# Z32F0641 register map
Vendor: Zilog, Inc; File version: 1.0
CPU: CM3 r1p0, little endian, no MPU, no FPU, 3 interrupt priority bits
Registers are 32-bit, read-write, reset 0x0 unless marked. A register's access mark holds for its fields unless they carry their own. Offsets are from the block's base; [hi:lo] are bit positions; {n}, {i} and the like mark numbered series.

## T0 — 16-BIT TIMER
Base 0x40003000
Same registers: T1 0x40003020, T2 0x40003040, T3 0x40003060, T8 0x40003100, T9 0x40003120
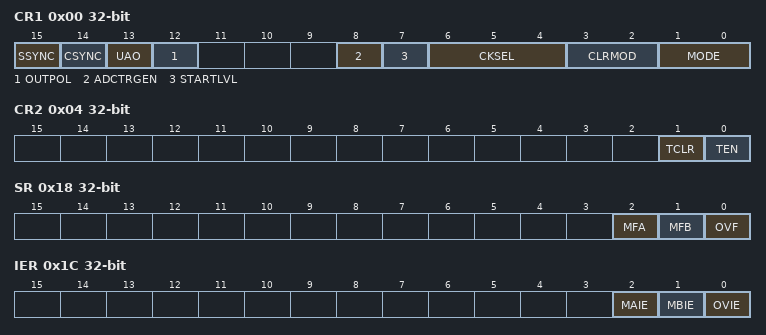
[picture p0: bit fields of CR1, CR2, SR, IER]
0x00 CR1 — Timer n Control Register 1
  [15] SSYNC — Syncronize Start Counter
  [14] CSYNC — Syncronize Clear Counter
  [13] UAO — GRA/GRB Update Mode
  [12] OUTPOL — Timer Output Polarity
  [8] ADCTRGEN
  [7] STARTLVL
  [6:4] CKSEL — counter clock source select
  [3:2] CLRMOD — clear select when capture mode
  [1:0] MODE — Timer operatin mode control
0x04 CR2 — Timer n Control Register 2
  [1] TCLR — Timer register clear
  [0] TEN — Timer enable bit
0x08 PRS — Timer n Prescaler Register
  [9:0] PRS — Prescaler value of count clock
0x0C GRA — Timer n General Register A
  [15:0] GRA
0x10 GRB — Timer n General Register B
  [15:0] GRB
0x14 CNT — Timer n Count Register
  [15:0] CNT
0x18 SR — Timer n Status Register
  [2] MFA — Match register A Flag
  [1] MFB — MATCH register B flag
  [0] OVF — counter overflow falg
0x1C IER — Timer n Interrupt Enable Register
  [2] MAIE — GRA Match interrupt enablee
  [1] MBIE — GRB Match interrupt enable
  [0] OVIE — Counter overflow interrupt enable

## U0 — UNIVERSAL ASYNCHRONOUS RECEIVER/TRANSMITTER
Base 0x40008000
Same registers: U1 0x40008100
0x00 RBR ro — Receive Buffer Register
  [7:0] RBR — recevied/transmit data
0x00 THR wo — Transmit Data Hold Register
  [7:0] THR — recevied/transmit data
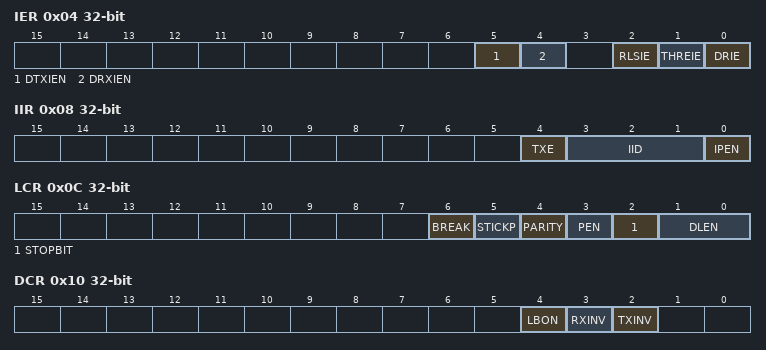
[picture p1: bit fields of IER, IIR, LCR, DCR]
0x04 IER — UART Interrupt Enable Register
  [5] DTXIEN — DMA transmit done interrupt enable
  [4] DRXIEN — DMA Receiver line status interrupt enable
  [2] RLSIE — receiver line status interrupt enable
  [1] THREIE — Transmit holding register empty interrupt enable
  [0] DRIE — Data receive interrupt enable
0x08 IIR — UART Interrupt ID Register
  [4] TXE — TX Interrupt
  [3:1] IID — Interrupt source ID
  [0] IPEN — Interrupt pending bit
0x0C LCR — UART Line Control Register
  [6] BREAK
  [5] STICKP — STICK
  [4] PARITY
  [3] PEN — parity bit transfer enable
  [2] STOPBIT
  [1:0] DLEN — Data length in one transfer word
0x10 DCR — UART Data Control Register
  [4] LBON — Local loopback test mode enable
  [3] RXINV — Rx Data Inversion selection
  [2] TXINV — TX Data Inversion selection
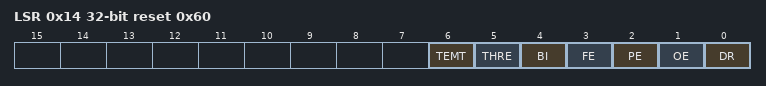
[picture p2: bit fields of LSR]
0x14 LSR reset 0x60 — UART Line Status Register
  [6] TEMT — Transmit empty
  [5] THRE — Transmit holding register empty
  [4] BI — break condition indication bit
  [3] FE — frame error
  [2] PE — parity error
  [1] OE — overrun error
  [0] DR — Data recevied
0x20 BDR — Baud rate Divisor Latch Register
  [15:0] BDR — baudrate setting
0x24 BFR — Baud rate Fraction Counter Register
  [7:0] BFR — Fraction counter value
0x30 IDTR — Inter-frame Delay Time Register
  [2:0] WAITVAL — wait time is decied by this value

## SP0 — SERIAL PERIPHERAL INTERFACE
Base 0x40009000
0x00 RDR ro — SPI n Receive Data Register
  [16:0] RDR — Data
0x00 TDR wo — SPI n Transmit Data Register
  [16:0] TDR — Data
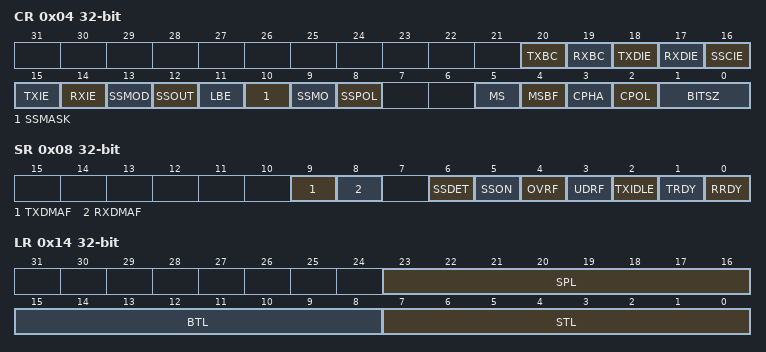
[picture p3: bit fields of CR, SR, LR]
0x04 CR — SPI n Control Register
  [20] TXBC — TX Buffer Clear bit
  [19] RXBC — Recieve buffer Clear bit
  [18] TXDIE — DMA TX Done Interrupt enable bit
  [17] RXDIE — DMA Rx Deone Interrupt enable bit
  [16] SSCIE — SSn Edge Chagne Interrupt enable bit
  [15] TXIE — Transmit interrupt enable bit
  [14] RXIE — Receive interrupt enable bit
  [13] SSMOD — SS Auto/Manual Output select bit
  [12] SSOUT — SS output signal select bit
  [11] LBE — Loop-back mode select bit in master mode
  [10] SSMASK — SS Signal masking bit in slave mode
  [9] SSMO — SS output signal select bit
  [8] SSPOL — SS Signal polarity select bit
  [5] MS — master/slaver select bit
  [4] MSBF — MSB/LSB transmit select bit
  [3] CPHA — SPI clock phase bit
  [2] CPOL — SPI clock polarity bit
  [1:0] BITSZ — Transmit/receive Data bits select bit
0x08 SR — SPI n Status Register
  [9] TXDMAF — DMA transmit Operation complete flag
  [8] RXDMAF — DMA receive Operation complete flag
  [6] SSDET — The rising edge of SS detect flag
  [5] SSON — SS signal status flag
  [4] OVRF — receive overrun error flag
  [3] UDRF — transmit underrun error flag
  [2] TXIDLE ro — transmit/receive operation flag
  [1] TRDY ro — Transmit buffer empty flag
  [0] RRDY ro — receive buffer ready flag
0x0C BR — SPI n Baud Rate Register
  [15:0] BR — buadrate
0x10 EN — SPI n Enable register
  [0] ENABLE — SPI ENABLE bit
0x14 LR — SPI n delay Length Register
  [23:16] SPL — Stop delay length
  [15:8] BTL — Burst delay length
  [7:0] STL — Start delay length

## IC0 — I2C Interface
Base 0x4000A000
0x00 DR — I2C Data Register
  [7:0] DR — Data
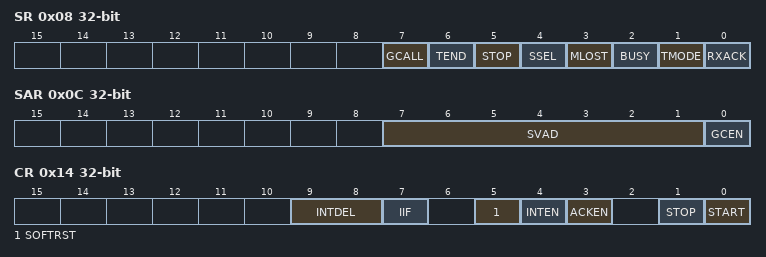
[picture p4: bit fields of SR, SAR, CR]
0x08 SR — Status register
  [7] GCALL — General call flag
  [6] TEND — 1 byte transmission complete flag
  [5] STOP — Stop Flag
  [4] SSEL — slave flag
  [3] MLOST — Mastership lost flag
  [2] BUSY — busy flag
  [1] TMODE — Transmit/reciever mode flag
  [0] RXACK — RX ack flag
0x0C SAR — I2C Slave Address Register
  [7:1] SVAD — 7 bits slave address
  [0] GCEN — general call enable bit
0x14 CR (reset mask 0xFF) — I2C Control Register
  [9:8] INTDEL — Interval Delay between Address and Data
  [7] IIF — Interrupt flag bit
  [5] SOFTRST — Soft reset enable bit
  [4] INTEN — Interrupt enable bit
  [3] ACKEN — ACK enabit bit in receiver mode
  [1] STOP — Stop enable bit
  [0] START — transmission start bit in master mode
0x18 SCLL reset 0xFFFF — I2C SCL LOW duration Register
  [15:0] SCLL — SCL Low duration value
0x1C SCLH reset 0xFFFF — I2C SCL HIGH duration Register
  [15:0] SCLH — SCL High duration value
0x20 SDH (reset mask 0x7F) — SDA Hold Register
  [14:0] SDH — SDA Hold time

## AD0 — 12-BIT A/D CONVERTER
Base 0x4000B000
Same registers: AD1 0x4000B100
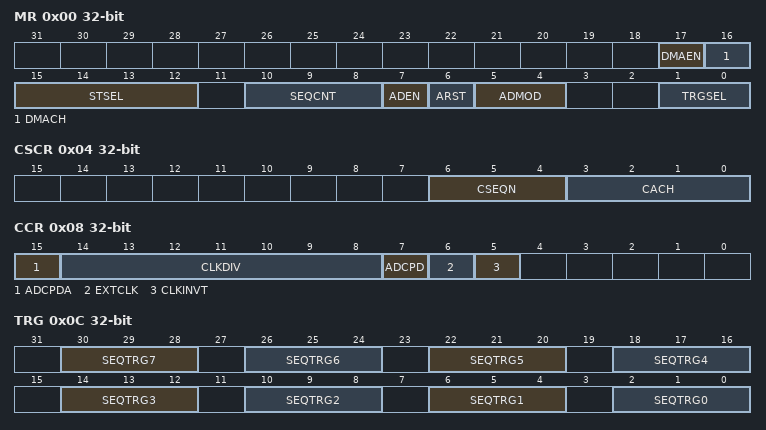
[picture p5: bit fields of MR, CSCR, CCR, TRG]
0x00 MR — ADCn Mode Register
  [17] DMAEN — DMA enable
  [16] DMACH — DMA channel option
  [15:12] STSEL — Sampling Time Selection
  [10:8] SEQCNT — Sequence Items Count
  [7] ADEN — ADC Enable
  [6] ARST — Stop/Restart at end of sequence
  [5:4] ADMOD — ADC convert mode
  [1:0] TRGSEL — ADC Trigger source sel
0x04 CSCR — ADCn Sequence/Channel Select Register
  [6:4] CSEQN — Current Sequence Number
  [3:0] CACH — Current Active Channel
0x08 CCR — ADCn Clock Control Register
  [15] ADCPDA — ADC R-ADC disable to save power
  [14:8] CLKDIV — ADC clock divider
  [7] ADCPD — ADC Power down
  [6] EXTCLK — ADCuse external clock
  [5] CLKINVT — divided clock inversion
0x0C TRG — ADC Trigger Selection Register
  [4n+2:4n] SEQTRG{n} (n=3..7) — {n+1}th Sequence Trigger Source
  [10:8] SEQTRG2 — 3rd Sequence Trigger Source
  [6:4] SEQTRG1 — 2ndh Sequence Trigger Source
  [2:0] SEQTRG0 — 1sth Sequence/Burst Trigger Source
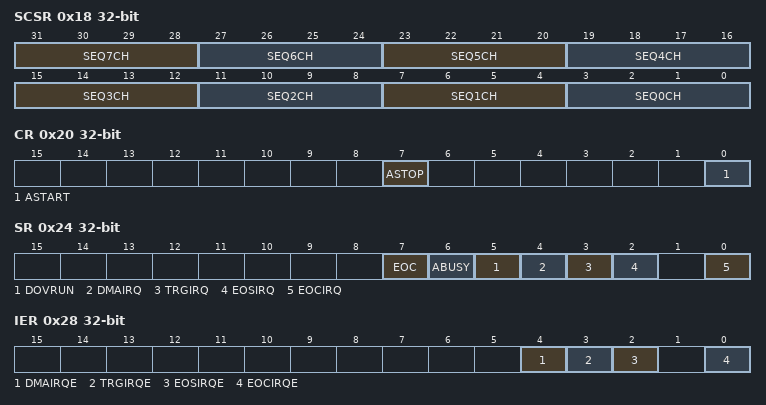
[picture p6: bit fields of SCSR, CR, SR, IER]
0x18 SCSR — ADC Sequence Channel select
  [4n+3:4n] SEQ{n}CH (n=3..7) — {n+1}th sequence coversion channel selection
  [11:8] SEQ2CH — 3rd sequence coversion channel selection
  [7:4] SEQ1CH — 2nd sequence coversion channel selection
  [3:0] SEQ0CH — 1st sequence coversion channel selection
0x20 CR — ADCn Control Register
  [7] ASTOP wo — ADC Stop
  [0] ASTART — ADC conversion start
0x24 SR — ADCn Status Register
  [7] EOC — End of Conversion Flag
  [6] ABUSY — ADC conversion busy flag
  [5] DOVRUN — DMA overrun flag
  [4] DMAIRQ — DMA received/transfer is done
  [3] TRGIRQ — ADC Trigger interrupt flag
  [2] EOSIRQ — ADC End of Sequence interrupt flag
  [0] EOCIRQ — Sequence Conversion Complete interrupt flag
0x28 IER — Interrupt Enable Register
  [4] DMAIRQE — DMA done interrupt enable
  [3] TRGIRQE — ADC Trigger conversion intterupt enable
  [2] EOSIRQE — ADC End of Sequence conversion interrupt enable
  [0] EOCIRQE — ADC Sequence Conversion Complete interrupt enable
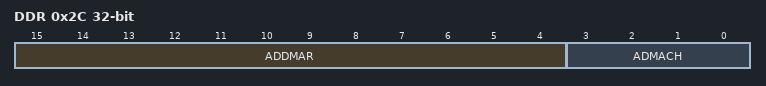
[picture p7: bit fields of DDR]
0x2C DDR — ADC DMA Data Register
  [15:4] ADDMAR — ADC conversion result data
  [3:0] ADMACH — ADC data channel indicator
{0x30+4i} DR{i} (i=0..7) — ADC Sequence {i} Data Register
  [15:4] ADCDATA ro — ADC Sequence Data
